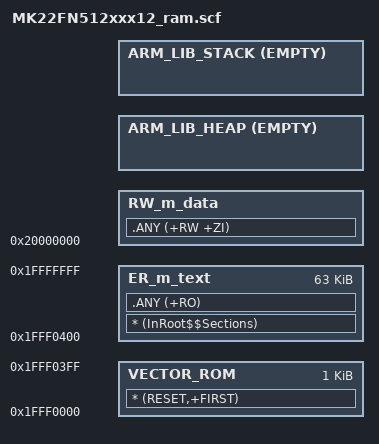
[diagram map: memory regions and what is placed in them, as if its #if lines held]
#! armcc -E
/*
** ###################################################################
**     Processors:          MK22FN512CAP12
**                          MK22FN512VDC12
**                          MK22FN512VFX12
**                          MK22FN512VLH12
**                          MK22FN512VLL12
**                          MK22FN512VMP12
**
**     Compiler:            Keil ARM C/C++ Compiler
**     Reference manual:    K22P121M120SF7RM, Rev. 1, March 24, 2014
**     Version:             rev. 2.9, 2016-03-21
**     Build:               b180801
**
**     Abstract:
**         Linker file for the Keil ARM C/C++ Compiler
**
**     Copyright 2016 Freescale Semiconductor, Inc.
**     Copyright 2016-2018 NXP
**
**     SPDX-License-Identifier: BSD-3-Clause
**
**     http:                 www.nxp.com
**     mail:                 support@nxp.com
**
** ###################################################################
*/

#define m_interrupts_start             0x1FFF0000
#define m_interrupts_size              0x00000400

#define m_text_start                   0x1FFF0400
#define m_text_size                    0x0000FC00

#define m_data_start                   0x20000000
#define m_data_size                    0x00010000

/* Sizes */
#if (defined(__stack_size__))
  #define Stack_Size                   __stack_size__
#else
  #define Stack_Size                   0x0400
#endif

#if (defined(__heap_size__))
  #define Heap_Size                    __heap_size__
#else
  #define Heap_Size                    0x0400
#endif

LR_m_text m_text_start m_text_size {   ; load region size_region
  ER_m_text m_text_start m_text_size { ; load address = execution address
    * (InRoot$$Sections)
    .ANY (+RO)
  }

  RW_m_data m_data_start m_data_size-Stack_Size-Heap_Size { ; RW data
    .ANY (+RW +ZI)
  }
  ARM_LIB_HEAP +0 EMPTY Heap_Size {    ; Heap region growing up
  }
  ARM_LIB_STACK m_data_start+m_data_size EMPTY -Stack_Size { ; Stack region growing down
  }
}

LR_m_interrupts m_interrupts_start m_interrupts_size {
  VECTOR_ROM m_interrupts_start m_interrupts_size { ; load address = execution address
    * (RESET,+FIRST)
  }
}

